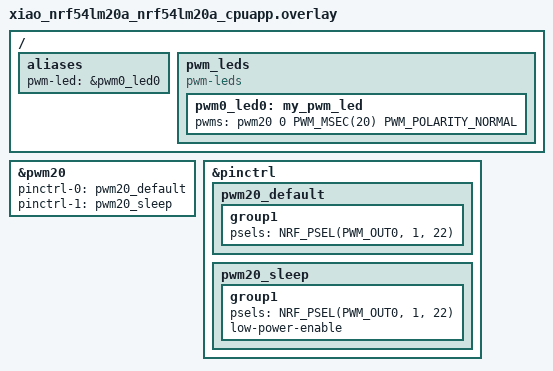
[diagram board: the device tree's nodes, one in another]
/ {
	aliases {
		pwm-led = &pwm0_led0;
	};

	pwm_leds {
		compatible = "pwm-leds";
		pwm0_led0: my_pwm_led {
			pwms = <&pwm20 0 PWM_MSEC(20) PWM_POLARITY_NORMAL>;
			status = "okay";
		};
	};
};

&pwm20 {
	status = "okay";
	pinctrl-0 = <&pwm20_default>;
	pinctrl-1 = <&pwm20_sleep>;
	pinctrl-names = "default", "sleep";
};

&pinctrl {
	/delete-node/ pwm20_default;
	/delete-node/ pwm20_sleep;

	pwm20_default: pwm20_default {
		group1 {
			psels = <NRF_PSEL(PWM_OUT0, 1, 22)>;
		};
	};

	pwm20_sleep: pwm20_sleep {
		group1 {
			psels = <NRF_PSEL(PWM_OUT0, 1, 22)>;
			low-power-enable;
		};
	};
};
